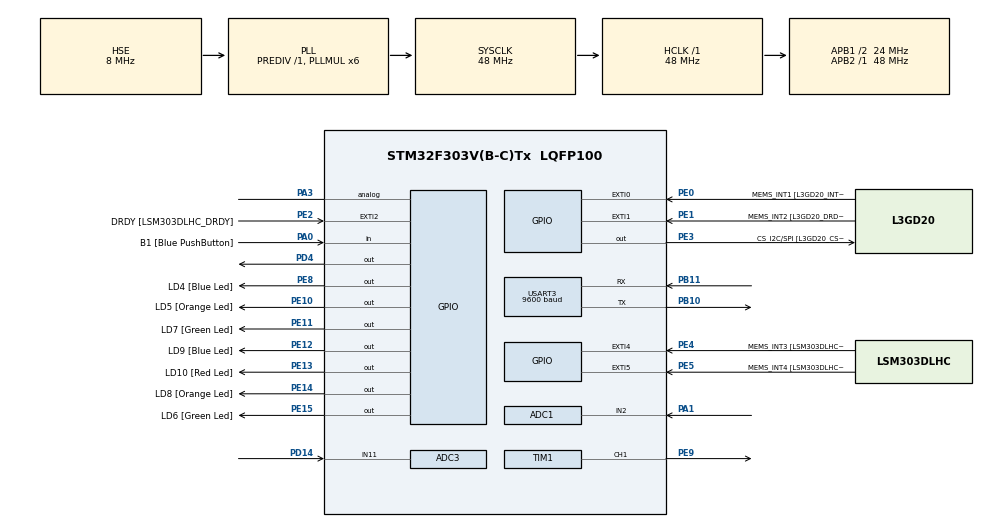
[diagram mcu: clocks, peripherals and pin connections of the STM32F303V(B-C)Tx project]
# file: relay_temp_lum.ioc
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ADC1.Channel-0\#ChannelRegularConversion=ADC_CHANNEL_2
ADC1.NbrOfConversionFlag=1
ADC1.Offset-0\#ChannelRegularConversion=0
ADC1.OffsetNumber-0\#ChannelRegularConversion=ADC_OFFSET_NONE
ADC1.Rank-0\#ChannelRegularConversion=1
ADC1.SamplingTime-0\#ChannelRegularConversion=ADC_SAMPLETIME_601CYCLES_5
ADC1.master=1
ADC3.Channel-2\#ChannelRegularConversion=ADC_CHANNEL_11
ADC3.NbrOfConversionFlag=1
ADC3.Offset-2\#ChannelRegularConversion=0
ADC3.OffsetNumber-2\#ChannelRegularConversion=ADC_OFFSET_NONE
ADC3.Rank-2\#ChannelRegularConversion=1
ADC3.SamplingTime-2\#ChannelRegularConversion=ADC_SAMPLETIME_601CYCLES_5
ADC3.SamplingTimeOPAMP-2\#ChannelRegularConversion=ADC_SAMPLETIME_19CYCLES_5
ADC3.master=1
Mcu.Family=STM32F3
Mcu.Name=STM32F303V(B-C)Tx
Mcu.Package=LQFP100
NVIC.ADC1_2_IRQn=true\:1\:0\:true\:false\:true\:true\:true
NVIC.ADC3_IRQn=true\:1\:1\:true\:false\:true\:true\:true
NVIC.PriorityGroup=NVIC_PRIORITYGROUP_2
NVIC.TIM3_IRQn=true\:2\:1\:true\:false\:true\:true\:true
NVIC.TIM4_IRQn=true\:2\:0\:true\:false\:true\:true\:true
PA0.GPIO_Label=B1 [Blue PushButton]
PA0.Signal=GPIO_Input
PA1.Mode=IN2-Single-Ended
PA1.Signal=ADC1_IN2
PA11.GPIO_Label=DM
PA11.Signal=USB_DM
PA12.GPIO_Label=DP
PA12.Signal=USB_DP
PA13.GPIO_Label=SWDIO
PA13.Mode=Serial_Wire
PA13.Signal=SYS_JTMS-SWDIO
PA14.GPIO_Label=SWCLK
PA14.Mode=Serial_Wire
PA14.Signal=SYS_JTCK-SWCLK
PA3.Signal=GPIO_Analog
PA5.GPIO_Label=SPI1_SCK [L3GD20_SCL/SPC]
PA5.Signal=SPI1_SCK
PA6.GPIO_Label=SPI1_MISO [L3GD20_SA0/SDO]
PA6.Signal=SPI1_MISO
PA7.GPIO_Label=SPI1_MISO [L3GD20_SDA/SDI/SDO]
PA7.Signal=SPI1_MOSI
PB10.Mode=Asynchronous
PB10.Signal=USART3_TX
PB11.Mode=Asynchronous
PB11.Signal=USART3_RX
PB3.GPIO_Label=SWO
PB3.Signal=SYS_JTDO-TRACESWO
PB6.GPIO_Label=I2C1_SCL [LSM303DLHC_SCL]
PB6.GPIO_Pu=GPIO_PULLUP
PB6.Signal=I2C1_SCL
PB7.GPIO_Label=I2C1_SDA [LSM303DLHC_SDA]
PB7.GPIO_Pu=GPIO_PULLUP
PB7.Signal=I2C1_SDA
PC14-OSC32_IN.GPIO_Label=OSC32_IN
PC14-OSC32_IN.Signal=RCC_OSC32_IN
PC15-OSC32_OUT.GPIO_Label=OSC32_OUT
PC15-OSC32_OUT.Signal=RCC_OSC32_OUT
PD14.Signal=ADCx_IN11
PD4.Signal=GPIO_Output
PE0.GPIO_Label=MEMS_INT1 [L3GD20_INT1]
PE0.GPIO_ModeDefaultEXTI=GPIO_MODE_EVT_RISING
PE0.Signal=GPXTI0
PE1.GPIO_Label=MEMS_INT2 [L3GD20_DRDY/INT2]
PE1.GPIO_ModeDefaultEXTI=GPIO_MODE_EVT_RISING
PE1.Signal=GPXTI1
PE10.GPIO_Label=LD5 [Orange Led]
PE10.Signal=GPIO_Output
PE11.GPIO_Label=LD7 [Green Led]
PE11.Signal=GPIO_Output
PE12.GPIO_Label=LD9 [Blue Led]
PE12.Signal=GPIO_Output
PE13.GPIO_Label=LD10 [Red Led]
PE13.Signal=GPIO_Output
PE14.GPIO_Label=LD8 [Orange Led]
PE14.Signal=GPIO_Output
PE15.GPIO_Label=LD6 [Green Led]
PE15.Signal=GPIO_Output
PE2.GPIO_Label=DRDY [LSM303DLHC_DRDY]
PE2.GPIO_ModeDefaultEXTI=GPIO_MODE_EVT_RISING
PE2.Signal=GPXTI2
PE3.GPIO_Label=CS_I2C/SPI [L3GD20_CS_I2C/SPI]
PE3.Signal=GPIO_Output
PE4.GPIO_Label=MEMS_INT3 [LSM303DLHC_INT1]
PE4.GPIO_ModeDefaultEXTI=GPIO_MODE_EVT_RISING
PE4.Signal=GPXTI4
PE5.GPIO_Label=MEMS_INT4 [LSM303DLHC_INT2]
PE5.GPIO_ModeDefaultEXTI=GPIO_MODE_EVT_RISING
PE5.Signal=GPXTI5
PE8.GPIO_Label=LD4 [Blue Led]
PE8.Signal=GPIO_Output
PE9.Signal=S_TIM1_CH1
PF0-OSC_IN.GPIO_Label=OSC_IN
PF0-OSC_IN.Mode=HSE-External-Clock-Source
PF0-OSC_IN.Signal=RCC_OSC_IN
PF1-OSC_OUT.GPIO_Label=OSC_OUT
PF1-OSC_OUT.Signal=RCC_OSC_OUT
ProjectManager.HeapSize=0x200
ProjectManager.StackSize=0x400
ProjectManager.TargetToolchain=STM32CubeIDE
RCC.AHBFreq_Value=48000000
RCC.APB1CLKDivider=RCC_HCLK_DIV2
RCC.APB1Freq_Value=24000000
RCC.APB1TimFreq_Value=48000000
RCC.APB2Freq_Value=48000000
RCC.APB2TimFreq_Value=48000000
RCC.CortexFreq_Value=48000000
RCC.HCLKFreq_Value=48000000
RCC.HSE_VALUE=8000000
RCC.HSI_VALUE=8000000
RCC.LSE_VALUE=32768
RCC.PLLMUL=RCC_PLL_MUL6
RCC.PLLSourceVirtual=RCC_PLLSOURCE_HSE
RCC.SYSCLKFreq_VALUE=48000000
RCC.SYSCLKSourceVirtual=RCC_SYSCLKSOURCE_PLLCLK
RCC.USBFreq_Value=48000000
SH.ADCx_IN11.0=ADC3_IN11,IN11-Single-Ended
SH.S_TIM1_CH1.0=TIM1_CH1,PWM Generation1 CH1
TIM1.Channel-PWM\ Generation1\ CH1=TIM_CHANNEL_1
TIM1.Period=99
TIM1.Prescaler=1
TIM3.Period=9999
TIM3.Prescaler=479
TIM4.Period=9999
TIM4.Prescaler=2399
USART3.BaudRate=9600
USART3.VirtualMode-Asynchronous=VM_ASYNC
VP_TIM1_VS_ClockSourceINT.Mode=Internal
VP_TIM3_VS_ClockSourceINT.Mode=Internal
VP_TIM4_VS_ClockSourceINT.Mode=Internal
board=STM32F3DISCOVERY

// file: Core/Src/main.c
/* USER CODE BEGIN Header */
/**
  ******************************************************************************
  * @file           : main.c
  * @brief          : Main program body
  ******************************************************************************
  * @attention
  *
  * <h2><center>&copy; Copyright (c) 2021 STMicroelectronics.
  * All rights reserved.</center></h2>
  *
  * This software component is licensed by ST under BSD 3-Clause license,
  * the "License"; You may not use this file except in compliance with the
  * License. You may obtain a copy of the License at:
  *                        opensource.org/licenses/BSD-3-Clause
  *
  ******************************************************************************
  */
/* USER CODE END Header */
#include "main.h"

ADC_HandleTypeDef hadc1;
ADC_HandleTypeDef hadc3;

TIM_HandleTypeDef htim1;
TIM_HandleTypeDef htim3;
TIM_HandleTypeDef htim4;

UART_HandleTypeDef huart3;

void SystemClock_Config(void);
static void MX_GPIO_Init(void);
static void MX_ADC1_Init(void);
static void MX_TIM1_Init(void);
static void MX_TIM3_Init(void);
static void MX_TIM4_Init(void);
static void MX_USART3_UART_Init(void);
static void MX_ADC3_Init(void);

int main(void)
{

  /* MCU Configuration--------------------------------------------------------*/

  /* Reset of all peripherals, Initializes the Flash interface and the Systick. */
  HAL_Init();

  /* Configure the system clock */
  SystemClock_Config();

  /* Initialize all configured peripherals */
  MX_GPIO_Init();
  MX_ADC1_Init();
  MX_TIM1_Init();
  MX_TIM3_Init();
  MX_TIM4_Init();
  MX_USART3_UART_Init();
  MX_ADC3_Init();
  /* USER CODE BEGIN 2 */
  HAL_TIM_PWM_Start(&htim1, TIM_CHANNEL_1);
  HAL_ADC_Start_IT(&hadc1);
  HAL_ADC_Start_IT(&hadc3);
  HAL_TIM_Base_Start_IT(&htim3);
  HAL_TIM_Base_Start_IT(&htim4);
  /* USER CODE END 2 */

  /* Infinite loop */
  while (1)
  {

  }
}

void SystemClock_Config(void)
{
  RCC_OscInitTypeDef RCC_OscInitStruct = {0};
  RCC_ClkInitTypeDef RCC_ClkInitStruct = {0};
  RCC_PeriphCLKInitTypeDef PeriphClkInit = {0};

  /** Initializes the RCC Oscillators according to the specified parameters
  * in the RCC_OscInitTypeDef structure.
  */
  RCC_OscInitStruct.OscillatorType = RCC_OSCILLATORTYPE_HSE;
  RCC_OscInitStruct.HSEState = RCC_HSE_BYPASS;
  RCC_OscInitStruct.HSEPredivValue = RCC_HSE_PREDIV_DIV1;
  RCC_OscInitStruct.HSIState = RCC_HSI_ON;
  RCC_OscInitStruct.PLL.PLLState = RCC_PLL_ON;
  RCC_OscInitStruct.PLL.PLLSource = RCC_PLLSOURCE_HSE;
  RCC_OscInitStruct.PLL.PLLMUL = RCC_PLL_MUL6;
  if (HAL_RCC_OscConfig(&RCC_OscInitStruct) != HAL_OK)
  {
    Error_Handler();
  }
  /** Initializes the CPU, AHB and APB buses clocks
  */
  RCC_ClkInitStruct.ClockType = RCC_CLOCKTYPE_HCLK|RCC_CLOCKTYPE_SYSCLK
                              |RCC_CLOCKTYPE_PCLK1|RCC_CLOCKTYPE_PCLK2;
  RCC_ClkInitStruct.SYSCLKSource = RCC_SYSCLKSOURCE_PLLCLK;
  RCC_ClkInitStruct.AHBCLKDivider = RCC_SYSCLK_DIV1;
  RCC_ClkInitStruct.APB1CLKDivider = RCC_HCLK_DIV2;
  RCC_ClkInitStruct.APB2CLKDivider = RCC_HCLK_DIV1;

  if (HAL_RCC_ClockConfig(&RCC_ClkInitStruct, FLASH_LATENCY_1) != HAL_OK)
  {
    Error_Handler();
  }
  PeriphClkInit.PeriphClockSelection = RCC_PERIPHCLK_USART3|RCC_PERIPHCLK_TIM1
                              |RCC_PERIPHCLK_ADC12|RCC_PERIPHCLK_ADC34;
  PeriphClkInit.Usart3ClockSelection = RCC_USART3CLKSOURCE_PCLK1;
  PeriphClkInit.Adc12ClockSelection = RCC_ADC12PLLCLK_DIV1;
  PeriphClkInit.Adc34ClockSelection = RCC_ADC34PLLCLK_DIV1;
  PeriphClkInit.Tim1ClockSelection = RCC_TIM1CLK_HCLK;
  if (HAL_RCCEx_PeriphCLKConfig(&PeriphClkInit) != HAL_OK)
  {
    Error_Handler();
  }
}

static void MX_ADC1_Init(void)
{

  ADC_MultiModeTypeDef multimode = {0};
  ADC_ChannelConfTypeDef sConfig = {0};

  /** Common config
  */
  hadc1.Instance = ADC1;
  hadc1.Init.ClockPrescaler = ADC_CLOCK_ASYNC_DIV1;
  hadc1.Init.Resolution = ADC_RESOLUTION_12B;
  hadc1.Init.ScanConvMode = ADC_SCAN_DISABLE;
  hadc1.Init.ContinuousConvMode = DISABLE;
  hadc1.Init.DiscontinuousConvMode = DISABLE;
  hadc1.Init.ExternalTrigConvEdge = ADC_EXTERNALTRIGCONVEDGE_NONE;
  hadc1.Init.ExternalTrigConv = ADC_SOFTWARE_START;
  hadc1.Init.DataAlign = ADC_DATAALIGN_RIGHT;
  hadc1.Init.NbrOfConversion = 1;
  hadc1.Init.DMAContinuousRequests = DISABLE;
  hadc1.Init.EOCSelection = ADC_EOC_SINGLE_CONV;
  hadc1.Init.LowPowerAutoWait = DISABLE;
  hadc1.Init.Overrun = ADC_OVR_DATA_OVERWRITTEN;
  if (HAL_ADC_Init(&hadc1) != HAL_OK)
  {
    Error_Handler();
  }
  /** Configure the ADC multi-mode
  */
  multimode.Mode = ADC_MODE_INDEPENDENT;
  if (HAL_ADCEx_MultiModeConfigChannel(&hadc1, &multimode) != HAL_OK)
  {
    Error_Handler();
  }
  /** Configure Regular Channel
  */
  sConfig.Channel = ADC_CHANNEL_2;
  sConfig.Rank = ADC_REGULAR_RANK_1;
  sConfig.SingleDiff = ADC_SINGLE_ENDED;
  sConfig.SamplingTime = ADC_SAMPLETIME_601CYCLES_5;
  sConfig.OffsetNumber = ADC_OFFSET_NONE;
  sConfig.Offset = 0;
  if (HAL_ADC_ConfigChannel(&hadc1, &sConfig) != HAL_OK)
  {
    Error_Handler();
  }

}

static void MX_ADC3_Init(void)
{

  ADC_MultiModeTypeDef multimode = {0};
  ADC_ChannelConfTypeDef sConfig = {0};

  /** Common config
  */
  hadc3.Instance = ADC3;
  hadc3.Init.ClockPrescaler = ADC_CLOCK_ASYNC_DIV1;
  hadc3.Init.Resolution = ADC_RESOLUTION_12B;
  hadc3.Init.ScanConvMode = ADC_SCAN_DISABLE;
  hadc3.Init.ContinuousConvMode = DISABLE;
  hadc3.Init.DiscontinuousConvMode = DISABLE;
  hadc3.Init.ExternalTrigConvEdge = ADC_EXTERNALTRIGCONVEDGE_NONE;
  hadc3.Init.ExternalTrigConv = ADC_SOFTWARE_START;
  hadc3.Init.DataAlign = ADC_DATAALIGN_RIGHT;
  hadc3.Init.NbrOfConversion = 1;
  hadc3.Init.DMAContinuousRequests = DISABLE;
  hadc3.Init.EOCSelection = ADC_EOC_SINGLE_CONV;
  hadc3.Init.LowPowerAutoWait = DISABLE;
  hadc3.Init.Overrun = ADC_OVR_DATA_OVERWRITTEN;
  if (HAL_ADC_Init(&hadc3) != HAL_OK)
  {
    Error_Handler();
  }
  /** Configure the ADC multi-mode
  */
  multimode.Mode = ADC_MODE_INDEPENDENT;
  if (HAL_ADCEx_MultiModeConfigChannel(&hadc3, &multimode) != HAL_OK)
  {
    Error_Handler();
  }
  /** Configure Regular Channel
  */
  sConfig.Channel = ADC_CHANNEL_11;
  sConfig.Rank = ADC_REGULAR_RANK_1;
  sConfig.SingleDiff = ADC_SINGLE_ENDED;
  sConfig.SamplingTime = ADC_SAMPLETIME_601CYCLES_5;
  sConfig.OffsetNumber = ADC_OFFSET_NONE;
  sConfig.Offset = 0;
  if (HAL_ADC_ConfigChannel(&hadc3, &sConfig) != HAL_OK)
  {
    Error_Handler();
  }

}

static void MX_TIM1_Init(void)
{

  TIM_ClockConfigTypeDef sClockSourceConfig = {0};
  TIM_MasterConfigTypeDef sMasterConfig = {0};
  TIM_OC_InitTypeDef sConfigOC = {0};
  TIM_BreakDeadTimeConfigTypeDef sBreakDeadTimeConfig = {0};

  htim1.Instance = TIM1;
  htim1.Init.Prescaler = 1;
  htim1.Init.CounterMode = TIM_COUNTERMODE_UP;
  htim1.Init.Period = 99;
  htim1.Init.ClockDivision = TIM_CLOCKDIVISION_DIV1;
  htim1.Init.RepetitionCounter = 0;
  htim1.Init.AutoReloadPreload = TIM_AUTORELOAD_PRELOAD_DISABLE;
  if (HAL_TIM_Base_Init(&htim1) != HAL_OK)
  {
    Error_Handler();
  }
  sClockSourceConfig.ClockSource = TIM_CLOCKSOURCE_INTERNAL;
  if (HAL_TIM_ConfigClockSource(&htim1, &sClockSourceConfig) != HAL_OK)
  {
    Error_Handler();
  }
  if (HAL_TIM_PWM_Init(&htim1) != HAL_OK)
  {
    Error_Handler();
  }
  sMasterConfig.MasterOutputTrigger = TIM_TRGO_RESET;
  sMasterConfig.MasterOutputTrigger2 = TIM_TRGO2_RESET;
  sMasterConfig.MasterSlaveMode = TIM_MASTERSLAVEMODE_DISABLE;
  if (HAL_TIMEx_MasterConfigSynchronization(&htim1, &sMasterConfig) != HAL_OK)
  {
    Error_Handler();
  }
  sConfigOC.OCMode = TIM_OCMODE_PWM1;
  sConfigOC.Pulse = 0;
  sConfigOC.OCPolarity = TIM_OCPOLARITY_HIGH;
  sConfigOC.OCNPolarity = TIM_OCNPOLARITY_HIGH;
  sConfigOC.OCFastMode = TIM_OCFAST_DISABLE;
  sConfigOC.OCIdleState = TIM_OCIDLESTATE_RESET;
  sConfigOC.OCNIdleState = TIM_OCNIDLESTATE_RESET;
  if (HAL_TIM_PWM_ConfigChannel(&htim1, &sConfigOC, TIM_CHANNEL_1) != HAL_OK)
  {
    Error_Handler();
  }
  sBreakDeadTimeConfig.OffStateRunMode = TIM_OSSR_DISABLE;
  sBreakDeadTimeConfig.OffStateIDLEMode = TIM_OSSI_DISABLE;
  sBreakDeadTimeConfig.LockLevel = TIM_LOCKLEVEL_OFF;
  sBreakDeadTimeConfig.DeadTime = 0;
  sBreakDeadTimeConfig.BreakState = TIM_BREAK_DISABLE;
  sBreakDeadTimeConfig.BreakPolarity = TIM_BREAKPOLARITY_HIGH;
  sBreakDeadTimeConfig.BreakFilter = 0;
  sBreakDeadTimeConfig.Break2State = TIM_BREAK2_DISABLE;
  sBreakDeadTimeConfig.Break2Polarity = TIM_BREAK2POLARITY_HIGH;
  sBreakDeadTimeConfig.Break2Filter = 0;
  sBreakDeadTimeConfig.AutomaticOutput = TIM_AUTOMATICOUTPUT_DISABLE;
  if (HAL_TIMEx_ConfigBreakDeadTime(&htim1, &sBreakDeadTimeConfig) != HAL_OK)
  {
    Error_Handler();
  }
  HAL_TIM_MspPostInit(&htim1);

}

static void MX_TIM3_Init(void)
{

  TIM_ClockConfigTypeDef sClockSourceConfig = {0};
  TIM_MasterConfigTypeDef sMasterConfig = {0};

  htim3.Instance = TIM3;
  htim3.Init.Prescaler = 479;
  htim3.Init.CounterMode = TIM_COUNTERMODE_UP;
  htim3.Init.Period = 9999;
  htim3.Init.ClockDivision = TIM_CLOCKDIVISION_DIV1;
  htim3.Init.AutoReloadPreload = TIM_AUTORELOAD_PRELOAD_DISABLE;
  if (HAL_TIM_Base_Init(&htim3) != HAL_OK)
  {
    Error_Handler();
  }
  sClockSourceConfig.ClockSource = TIM_CLOCKSOURCE_INTERNAL;
  if (HAL_TIM_ConfigClockSource(&htim3, &sClockSourceConfig) != HAL_OK)
  {
    Error_Handler();
  }
  sMasterConfig.MasterOutputTrigger = TIM_TRGO_RESET;
  sMasterConfig.MasterSlaveMode = TIM_MASTERSLAVEMODE_DISABLE;
  if (HAL_TIMEx_MasterConfigSynchronization(&htim3, &sMasterConfig) != HAL_OK)
  {
    Error_Handler();
  }

}

static void MX_TIM4_Init(void)
{

  TIM_ClockConfigTypeDef sClockSourceConfig = {0};
  TIM_MasterConfigTypeDef sMasterConfig = {0};

  htim4.Instance = TIM4;
  htim4.Init.Prescaler = 2399;
  htim4.Init.CounterMode = TIM_COUNTERMODE_UP;
  htim4.Init.Period = 9999;
  htim4.Init.ClockDivision = TIM_CLOCKDIVISION_DIV1;
  htim4.Init.AutoReloadPreload = TIM_AUTORELOAD_PRELOAD_DISABLE;
  if (HAL_TIM_Base_Init(&htim4) != HAL_OK)
  {
    Error_Handler();
  }
  sClockSourceConfig.ClockSource = TIM_CLOCKSOURCE_INTERNAL;
  if (HAL_TIM_ConfigClockSource(&htim4, &sClockSourceConfig) != HAL_OK)
  {
    Error_Handler();
  }
  sMasterConfig.MasterOutputTrigger = TIM_TRGO_RESET;
  sMasterConfig.MasterSlaveMode = TIM_MASTERSLAVEMODE_DISABLE;
  if (HAL_TIMEx_MasterConfigSynchronization(&htim4, &sMasterConfig) != HAL_OK)
  {
    Error_Handler();
  }

}

static void MX_USART3_UART_Init(void)
{

  huart3.Instance = USART3;
  huart3.Init.BaudRate = 9600;
  huart3.Init.WordLength = UART_WORDLENGTH_8B;
  huart3.Init.StopBits = UART_STOPBITS_1;
  huart3.Init.Parity = UART_PARITY_NONE;
  huart3.Init.Mode = UART_MODE_TX_RX;
  huart3.Init.HwFlowCtl = UART_HWCONTROL_NONE;
  huart3.Init.OverSampling = UART_OVERSAMPLING_16;
  huart3.Init.OneBitSampling = UART_ONE_BIT_SAMPLE_DISABLE;
  huart3.AdvancedInit.AdvFeatureInit = UART_ADVFEATURE_NO_INIT;
  if (HAL_UART_Init(&huart3) != HAL_OK)
  {
    Error_Handler();
  }

}

static void MX_GPIO_Init(void)
{
  GPIO_InitTypeDef GPIO_InitStruct = {0};

  /* GPIO Ports Clock Enable */
  __HAL_RCC_GPIOE_CLK_ENABLE();
  __HAL_RCC_GPIOC_CLK_ENABLE();
  __HAL_RCC_GPIOF_CLK_ENABLE();
  __HAL_RCC_GPIOA_CLK_ENABLE();
  __HAL_RCC_GPIOB_CLK_ENABLE();
  __HAL_RCC_GPIOD_CLK_ENABLE();

  /*Configure GPIO pin Output Level */
  HAL_GPIO_WritePin(GPIOE, CS_I2C_SPI_Pin|LD4_Pin|LD5_Pin|LD7_Pin
                          |LD9_Pin|LD10_Pin|LD8_Pin|LD6_Pin, GPIO_PIN_RESET);

  /*Configure GPIO pin Output Level */
  HAL_GPIO_WritePin(GPIOD, GPIO_PIN_4, GPIO_PIN_RESET);

  /*Configure GPIO pins : DRDY_Pin MEMS_INT3_Pin MEMS_INT4_Pin MEMS_INT1_Pin
                           MEMS_INT2_Pin */
  GPIO_InitStruct.Pin = DRDY_Pin|MEMS_INT3_Pin|MEMS_INT4_Pin|MEMS_INT1_Pin
                          |MEMS_INT2_Pin;
  GPIO_InitStruct.Mode = GPIO_MODE_EVT_RISING;
  GPIO_InitStruct.Pull = GPIO_NOPULL;
  HAL_GPIO_Init(GPIOE, &GPIO_InitStruct);

  /*Configure GPIO pins : CS_I2C_SPI_Pin LD4_Pin LD5_Pin LD7_Pin
                           LD9_Pin LD10_Pin LD8_Pin LD6_Pin */
  GPIO_InitStruct.Pin = CS_I2C_SPI_Pin|LD4_Pin|LD5_Pin|LD7_Pin
                          |LD9_Pin|LD10_Pin|LD8_Pin|LD6_Pin;
  GPIO_InitStruct.Mode = GPIO_MODE_OUTPUT_PP;
  GPIO_InitStruct.Pull = GPIO_NOPULL;
  GPIO_InitStruct.Speed = GPIO_SPEED_FREQ_LOW;
  HAL_GPIO_Init(GPIOE, &GPIO_InitStruct);

  /*Configure GPIO pin : B1_Pin */
  GPIO_InitStruct.Pin = B1_Pin;
  GPIO_InitStruct.Mode = GPIO_MODE_INPUT;
  GPIO_InitStruct.Pull = GPIO_NOPULL;
  HAL_GPIO_Init(B1_GPIO_Port, &GPIO_InitStruct);

  /*Configure GPIO pin : PA3 */
  GPIO_InitStruct.Pin = GPIO_PIN_3;
  GPIO_InitStruct.Mode = GPIO_MODE_ANALOG;
  GPIO_InitStruct.Pull = GPIO_NOPULL;
  HAL_GPIO_Init(GPIOA, &GPIO_InitStruct);

  /*Configure GPIO pins : SPI1_SCK_Pin SPI1_MISO_Pin SPI1_MISOA7_Pin */
  GPIO_InitStruct.Pin = SPI1_SCK_Pin|SPI1_MISO_Pin|SPI1_MISOA7_Pin;
  GPIO_InitStruct.Mode = GPIO_MODE_AF_PP;
  GPIO_InitStruct.Pull = GPIO_NOPULL;
  GPIO_InitStruct.Speed = GPIO_SPEED_FREQ_HIGH;
  GPIO_InitStruct.Alternate = GPIO_AF5_SPI1;
  HAL_GPIO_Init(GPIOA, &GPIO_InitStruct);

  /*Configure GPIO pins : DM_Pin DP_Pin */
  GPIO_InitStruct.Pin = DM_Pin|DP_Pin;
  GPIO_InitStruct.Mode = GPIO_MODE_AF_PP;
  GPIO_InitStruct.Pull = GPIO_NOPULL;
  GPIO_InitStruct.Speed = GPIO_SPEED_FREQ_HIGH;
  GPIO_InitStruct.Alternate = GPIO_AF14_USB;
  HAL_GPIO_Init(GPIOA, &GPIO_InitStruct);

  /*Configure GPIO pin : PD4 */
  GPIO_InitStruct.Pin = GPIO_PIN_4;
  GPIO_InitStruct.Mode = GPIO_MODE_OUTPUT_PP;
  GPIO_InitStruct.Pull = GPIO_NOPULL;
  GPIO_InitStruct.Speed = GPIO_SPEED_FREQ_LOW;
  HAL_GPIO_Init(GPIOD, &GPIO_InitStruct);

  /*Configure GPIO pins : I2C1_SCL_Pin I2C1_SDA_Pin */
  GPIO_InitStruct.Pin = I2C1_SCL_Pin|I2C1_SDA_Pin;
  GPIO_InitStruct.Mode = GPIO_MODE_AF_OD;
  GPIO_InitStruct.Pull = GPIO_PULLUP;
  GPIO_InitStruct.Speed = GPIO_SPEED_FREQ_HIGH;
  GPIO_InitStruct.Alternate = GPIO_AF4_I2C1;
  HAL_GPIO_Init(GPIOB, &GPIO_InitStruct);

}

void Error_Handler(void)
{
  __disable_irq();
  while (1)
  {
  }
}

/************************ (C) COPYRIGHT STMicroelectronics *****END OF FILE****/
